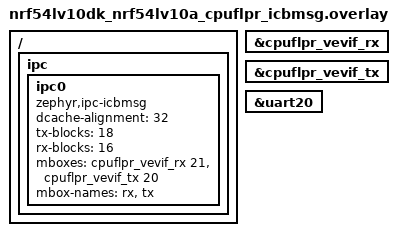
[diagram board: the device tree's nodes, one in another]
/*
 * Copyright (c) 2025 Nordic Semiconductor ASA
 *
 * SPDX-License-Identifier: LicenseRef-Nordic-5-Clause
 */

/ {
	ipc {
		ipc0: ipc0 {
			compatible = "zephyr,ipc-icbmsg";
			dcache-alignment = <32>;
			tx-blocks = <18>;
			rx-blocks = <16>;
			mboxes = <&cpuflpr_vevif_rx 21>, <&cpuflpr_vevif_tx 20>;
			mbox-names = "rx", "tx";
			status = "okay";
		};
	};
};

&cpuflpr_vevif_rx {
	status = "okay";
};

&cpuflpr_vevif_tx {
	status = "okay";
};

&uart20 {
	/delete-property/ hw-flow-control;
};
